# RS14100 register map
File version: 1.0
CPU: CM4 r0p1, little endian, MPU, FPU, 4 interrupt priority bits
Registers are 32-bit, read-write, reset 0x0 unless marked. A register's access mark holds for its fields unless they carry their own. Offsets are from the block's base; [hi:lo] are bit positions; lines under a group give offsets from that group; {n}, {i} and the like mark numbered series.

## RPDMA_G — RPDMAC is an AMBA complaint peripheral unit supports 8-channels
Base 0x21081084
0x00 GLOBAL group
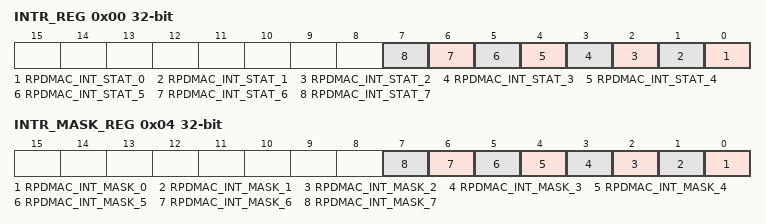
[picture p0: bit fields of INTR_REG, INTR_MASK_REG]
  0x00 INTR_REG — Interrupt Register
    [n] RPDMAC_INT_STAT_{n} (n=0..7) — Interrupt Status
      1=Enable (channel {n}, interrupt event has happened.); 0=Disable (channel {n}, interrupt event has not happened.)
  0x04 INTR_MASK_REG — Interrupt Mask Register
    [n] RPDMAC_INT_MASK_{n} (n=0..7) — Interrupt Mask for channel {n}
      1=Enable (channel {n} interrupt Mask); 0=Disable (channel {n} interrupt not Masked)

## MCUHP_MISC_CLOCK — MCU HP (High Performance) domain contains the Cortex-M4F Processor, FPU, Debugger, MCU High Speed Interfaces, MCU HP Peripherals, MCU HP DMA and MCU/SZP shareable Interfaces
Base 0x46008000
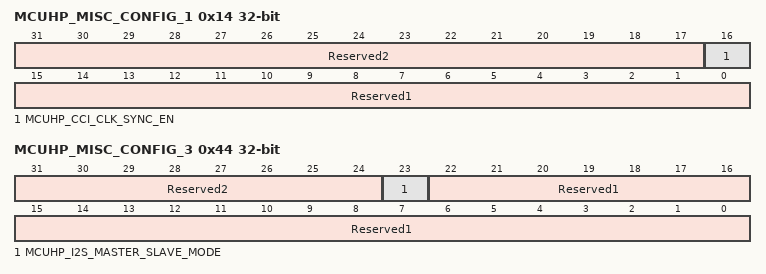
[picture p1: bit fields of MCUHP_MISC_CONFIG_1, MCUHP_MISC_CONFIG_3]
0x14 MCUHP_MISC_CONFIG_1 — Miscellaneous Clock Configuration Register1
  [31:17] Reserved2 — It is recommended to retain the contents by using read/modify write to this register.
  [16] MCUHP_CCI_CLK_SYNC_EN — Specifies the clock dependency w.r.t processor clock used for MCUHP CCI
    0=Independent clock source; 1=Undivided version of Processor Clock
  [15:0] Reserved1 — It is recommended to retain the contents by using read/modify write to this register.
0x44 MCUHP_MISC_CONFIG_3 — Miscellaneous Clock Configuration Register1
  [31:24] Reserved2 — It is recommended to retain the contents by using read/modify write to this register.
  [23] MCUHP_I2S_MASTER_SLAVE_MODE — Writing 1 to this configures I2S controller to Master Mode.Writing 0 to this configures I2S controller to Slave Mode.
  [22:0] Reserved1 — It is recommended to retain the contents by using read/modify write to this register.

## COMPARATOR_1 — Analog comparators is a peripheral circuit that consists of two comparators, reference buffer, scaler and a resistor bank
Base 0x24043A00
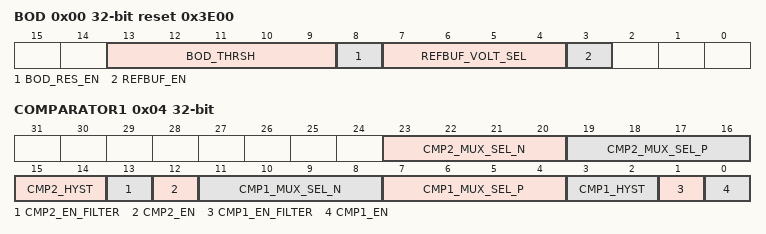
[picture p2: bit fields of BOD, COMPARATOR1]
0x00 BOD reset 0x3E00 — Programs resistor bank, reference buffer and scaler
  [13:9] BOD_THRSH — Programmability for resistor bank
  [8] BOD_RES_EN — configuration of register bank 1 for enable and 0 for disable
  [7:4] REFBUF_VOLT_SEL — selection of voltage of reference buffer
  [3] REFBUF_EN — Referance buffer configuration 1 for enable 0 for disable
0x04 COMPARATOR1 — Programs comparators1 and comparators2
  [23:20] CMP2_MUX_SEL_N — Select for negative input of comparator_2
  [19:16] CMP2_MUX_SEL_P — Select for positive input of comparator_2
  [15:14] CMP2_HYST — Programmability to control hysteresis of comparator2
  [13] CMP2_EN_FILTER — enable filter for comparator_2 if 1 enables the filter
  [12] CMP2_EN — enable comparator_2 if 1 comp_2 will enable
  [11:8] CMP1_MUX_SEL_N — Select for negative input of comparator_1
  [7:4] CMP1_MUX_SEL_P — Select for positive input of comparator_1
  [3:2] CMP1_HYST — Programmability to control hysteresis of comparator1
  [1] CMP1_EN_FILTER — enable filter for comparator_1 if 1 enables the filter
  [0] CMP1_EN — enable comparator_1 if 1 comp_1 will enable

## OPAMP — The opamps top consists of 3 general purpose Operational Amplifiers (OPAMP) offering rail-to-rail inputs and outputs
Base 0x24043A14
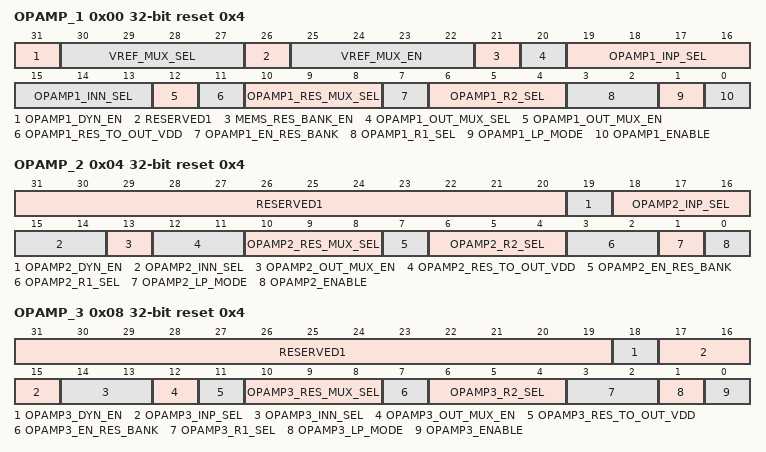
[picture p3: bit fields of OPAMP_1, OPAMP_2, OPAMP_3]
0x00 OPAMP_1 reset 0x4 — Programs opamp1
  [31] OPAMP1_DYN_EN — dynamic enable for opamp1
  [30:27] VREF_MUX_SEL — vref mux enable
  [26] RESERVED1 — res
  [25:22] VREF_MUX_EN — vref mux enable
  [21] MEMS_RES_BANK_EN — enables mems res bank
  [20] OPAMP1_OUT_MUX_SEL — to connect opamp1 output to pad
  [19:16] OPAMP1_INP_SEL — selecting +ve input of opamp
  [15:13] OPAMP1_INN_SEL — selecting -ve input of opamp
  [12] OPAMP1_OUT_MUX_EN — out mux enable
  [11] OPAMP1_RES_TO_OUT_VDD — connect resistor bank to out or vdd i.e 0-out and 1-vdd
  [10:8] OPAMP1_RES_MUX_SEL — selecting input for registor bank
  [7] OPAMP1_EN_RES_BANK — enables the resistor bank 1 for enable 0 for disable
  [6:4] OPAMP1_R2_SEL — Programmability to select resister bank R2
  [3:2] OPAMP1_R1_SEL — Programmability to select resister bank R1
  [1] OPAMP1_LP_MODE — select the power mode 0-normal mode and 1-low power mode
  [0] OPAMP1_ENABLE — enables the opamp 1 for enable 0 for disable
0x04 OPAMP_2 reset 0x4 — Programs opamp2
  [31:20] RESERVED1 — res
  [19] OPAMP2_DYN_EN — dynamic enable for opamp2
  [18:16] OPAMP2_INP_SEL — selecting +ve input of opamp
  [15:14] OPAMP2_INN_SEL — selecting -ve input of opamp
  [13] OPAMP2_OUT_MUX_EN — out mux enable
  [12:11] OPAMP2_RES_TO_OUT_VDD — connect resistor bank to out or vdd or gnd or DAC i.e 0-out and 1-vdd 2-DAC 3-gnd
  [10:8] OPAMP2_RES_MUX_SEL — selecting input for registor bank
  [7] OPAMP2_EN_RES_BANK — enables the resistor bank 1 for enable 0 for disable
  [6:4] OPAMP2_R2_SEL — Programmability to select resister bank R2
  [3:2] OPAMP2_R1_SEL — Programmability to select resister bank R1
  [1] OPAMP2_LP_MODE — select the power mode 0-normal mode and 1-low power mode
  [0] OPAMP2_ENABLE — enables the opamp 1 for enable 0 for disable
0x08 OPAMP_3 reset 0x4 — Programs opamp3
  [31:19] RESERVED1 — res
  [18] OPAMP3_DYN_EN — dynamic enable for opamp2
  [17:15] OPAMP3_INP_SEL — selecting +ve input of opamp
  [14:13] OPAMP3_INN_SEL — selecting -ve input of opamp
  [12] OPAMP3_OUT_MUX_EN — out mux enable
  [11] OPAMP3_RES_TO_OUT_VDD — connect resistor bank to out or vdd i.e 0-out and 1-vdd
  [10:8] OPAMP3_RES_MUX_SEL — selecting input for registor bank
  [7] OPAMP3_EN_RES_BANK — enables the resistor bank 1 for enable 0 for disable
  [6:4] OPAMP3_R2_SEL — Programmability to select resister bank R2
  [3:2] OPAMP3_R1_SEL — Programmability to select resister bank R1
  [1] OPAMP3_LP_MODE — select the power mode 0-normal mode and 1-low power mode
  [0] OPAMP3_ENABLE — enables the opamp 1 for enable 0 for disable

## IR — IR Decoder are used for the decoding the external ir sensor input.
Base 0x24040C00
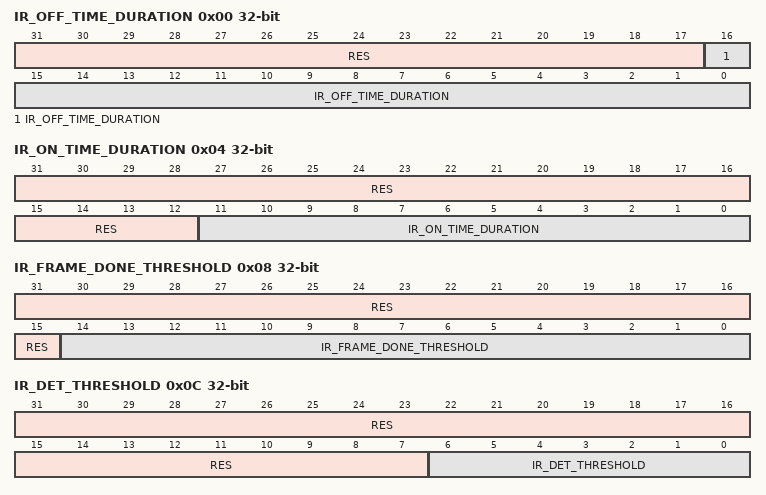
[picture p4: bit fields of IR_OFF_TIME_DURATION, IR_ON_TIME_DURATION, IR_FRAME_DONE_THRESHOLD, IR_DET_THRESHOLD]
0x00 IR_OFF_TIME_DURATION reset not defined — This register used for IR sleep duration timer value.
  [31:17] RES ro — reserved5
  [16:0] IR_OFF_TIME_DURATION — This field define ir off time
0x04 IR_ON_TIME_DURATION reset not defined — This register used for IR Detection duration timer value.
  [31:12] RES ro — reserved5
  [11:0] IR_ON_TIME_DURATION — This field define ir on time for ir detection on
0x08 IR_FRAME_DONE_THRESHOLD reset not defined — This register used count with respect to 32KHz clock after not more toggle are expected to a given pattern.
  [31:15] RES ro — reserved5
  [14:0] IR_FRAME_DONE_THRESHOLD — count with respect to 32KHz clock after not more toggle are expected to a given pattern
0x0C IR_DET_THRESHOLD reset not defined — This register used Minimum Number of edges to detected during on-time failing which IR detection is re-stated.
  [31:7] RES ro — reserved5
  [6:0] IR_DET_THRESHOLD — Minimum Number of edges to detected during on-time failing which IR detection is re-stated.
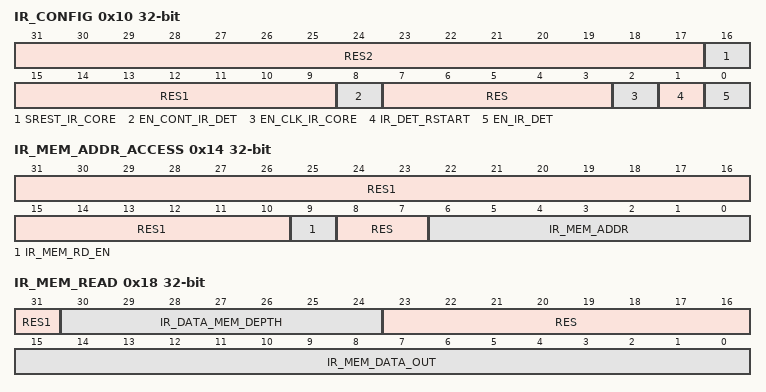
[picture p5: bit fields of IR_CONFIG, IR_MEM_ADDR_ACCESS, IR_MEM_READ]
0x10 IR_CONFIG reset not defined — This register used to configure the ir structure for application purpose.
  [31:17] RES2 ro — reserved7
  [16] SREST_IR_CORE — This bit is used soft reset IR core block
  [15:9] RES1 ro — reserved6
  [8] EN_CONT_IR_DET — This bit is Enable continues IR detection,When enabled there will be no power cycling on External IR Sensor.
  [7:3] RES ro — reserved5
  [2] EN_CLK_IR_CORE — Enable 32KHz clock to IR Core bit ,if bit 1 then clock gating disable and bit is 0 then clock gating Enable
  [1] IR_DET_RSTART — Enable IR detection re-start logic bit if bit 1 then re-start.
  [0] EN_IR_DET — Enable IR detection logic bit if bit 1 then detection enable if 0 then not enable.
0x14 IR_MEM_ADDR_ACCESS reset not defined — This register used to access memory address for application purpose.
  [31:10] RES1 ro — reserved6
  [9] IR_MEM_RD_EN — This field used to IR memory read enable.
  [8:7] RES ro — reserved5
  [6:0] IR_MEM_ADDR — This field is used to IR read address.
0x18 IR_MEM_READ ro reset not defined — This register used to IR Read data from memory.
  [31] RES1 — reserved6
  [30:24] IR_DATA_MEM_DEPTH — This field used to indicated valid number of IR Address in the memory to be read.
  [23:16] RES — reserved5
  [15:0] IR_MEM_DATA_OUT — This field is used to IR Read data from memory.
